AUTOSAR XML (schema 4-0-3)
standard types defined: Boolean, UInt16, UInt32
package /AUTOSAR_Platform/DataConstrs
  range DC_Boolean: raw 0..1
  range DC_UInt16: raw 0..65535
package /PATAC/MSM/ComponentTypes
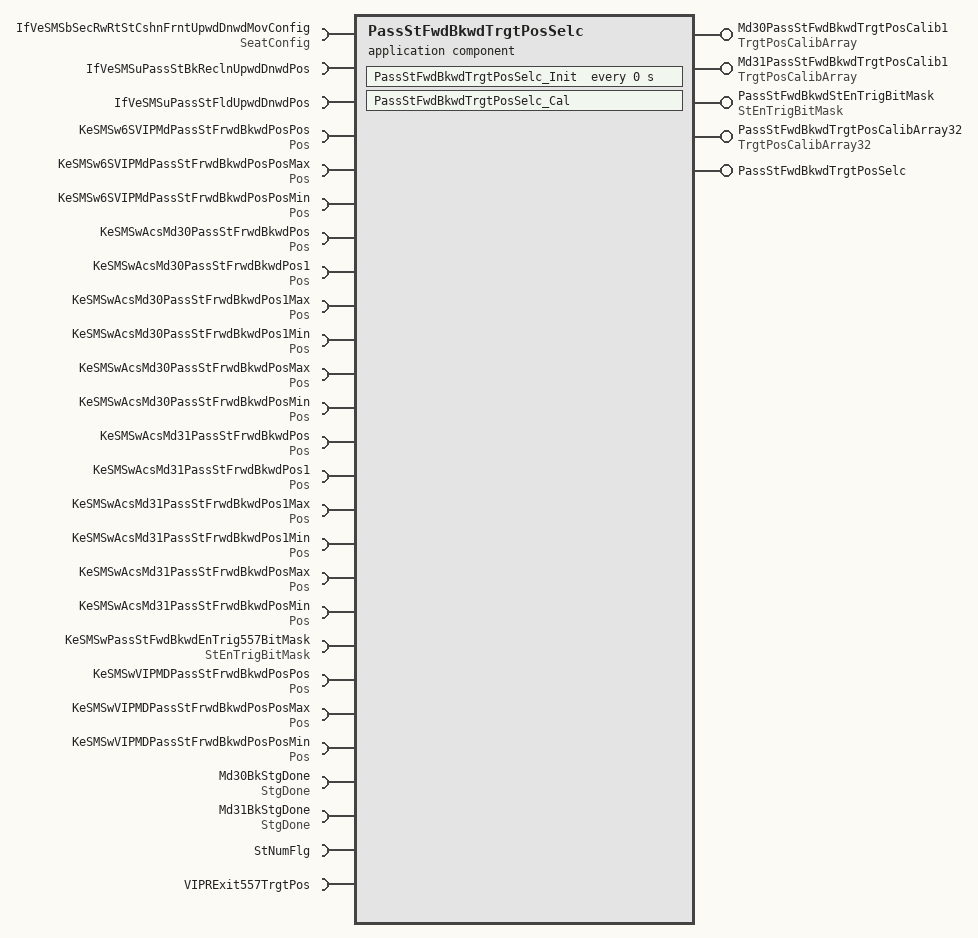
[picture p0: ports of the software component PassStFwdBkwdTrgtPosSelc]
  application sw component type PassStFwdBkwdTrgtPosSelc
    5 x provide port:
      Md30PassStFwdBkwdTrgtPosCalib1: nonqueued-sender-com-spec{data-element=TrgtPosArray, init-value=[4095, 4095, 4095]}, provided-interface=TrgtPosCalibArray
      Md31PassStFwdBkwdTrgtPosCalib1: nonqueued-sender-com-spec{data-element=TrgtPosArray, init-value=[4095, 4095, 4095]}, provided-interface=TrgtPosCalibArray
      PassStFwdBkwdStEnTrigBitMask: nonqueued-sender-com-spec{data-element=StEnTrigBitMask/Val, init-value=0}, provided-interface=StEnTrigBitMask
      PassStFwdBkwdTrgtPosCalibArray32: nonqueued-sender-com-spec{data-element=TrgtPosArray32, init-value=96 x 4095}, provided-interface=TrgtPosCalibArray32
      PassStFwdBkwdTrgtPosSelc: server-com-spec{operation=Cal, queue-length=1}, provided-interface=PassStFwdBkwdTrgtPosSelc
    26 x require port:
      IfVeSMSbSecRwRtStCshnFrntUpwdDnwdMovConfig: nonqueued-receiver-com-spec{data-element=SeatConfig/Val, filter=data-filter-type=ALWAYS, init-value=0}, required-interface=SeatConfig
      IfVeSMSuPassStBkReclnUpwdDnwdPos: nonqueued-receiver-com-spec{data-element=IfVeSMSuPassStBkReclnUpwdDnwdPos/Val, filter=data-filter-type=ALWAYS, init-value=0}, required-interface=IfVeSMSuPassStBkReclnUpwdDnwdPos
      IfVeSMSuPassStFldUpwdDnwdPos: nonqueued-receiver-com-spec{data-element=IfVeSMSuPassStFldUpwdDnwdPos/Val, filter=data-filter-type=ALWAYS, init-value=0}, required-interface=IfVeSMSuPassStFldUpwdDnwdPos
      KeSMSw6SVIPMdPassStFrwdBkwdPosPos: parameter-require-com-spec{init-value=0, parameter=Pos/Val}, required-interface=Pos
      KeSMSw6SVIPMdPassStFrwdBkwdPosPosMax: parameter-require-com-spec{init-value=0, parameter=Pos/Val}, required-interface=Pos
      KeSMSw6SVIPMdPassStFrwdBkwdPosPosMin: parameter-require-com-spec{init-value=0, parameter=Pos/Val}, required-interface=Pos
      KeSMSwAcsMd30PassStFrwdBkwdPos: parameter-require-com-spec{init-value=0, parameter=Pos/Val}, required-interface=Pos
      KeSMSwAcsMd30PassStFrwdBkwdPos1: parameter-require-com-spec{init-value=0, parameter=Pos/Val}, required-interface=Pos
      KeSMSwAcsMd30PassStFrwdBkwdPos1Max: parameter-require-com-spec{init-value=0, parameter=Pos/Val}, required-interface=Pos
      KeSMSwAcsMd30PassStFrwdBkwdPos1Min: parameter-require-com-spec{init-value=0, parameter=Pos/Val}, required-interface=Pos
      KeSMSwAcsMd30PassStFrwdBkwdPosMax: parameter-require-com-spec{init-value=0, parameter=Pos/Val}, required-interface=Pos
      KeSMSwAcsMd30PassStFrwdBkwdPosMin: parameter-require-com-spec{init-value=0, parameter=Pos/Val}, required-interface=Pos
      KeSMSwAcsMd31PassStFrwdBkwdPos: parameter-require-com-spec{init-value=0, parameter=Pos/Val}, required-interface=Pos
      KeSMSwAcsMd31PassStFrwdBkwdPos1: parameter-require-com-spec{init-value=0, parameter=Pos/Val}, required-interface=Pos
      KeSMSwAcsMd31PassStFrwdBkwdPos1Max: parameter-require-com-spec{init-value=0, parameter=Pos/Val}, required-interface=Pos
      KeSMSwAcsMd31PassStFrwdBkwdPos1Min: parameter-require-com-spec{init-value=0, parameter=Pos/Val}, required-interface=Pos
      KeSMSwAcsMd31PassStFrwdBkwdPosMax: parameter-require-com-spec{init-value=0, parameter=Pos/Val}, required-interface=Pos
      KeSMSwAcsMd31PassStFrwdBkwdPosMin: parameter-require-com-spec{init-value=0, parameter=Pos/Val}, required-interface=Pos
      KeSMSwPassStFwdBkwdEnTrig557BitMask: parameter-require-com-spec{init-value=6153, parameter=StEnTrigBitMask/Val}, required-interface=StEnTrigBitMask
      KeSMSwVIPMDPassStFrwdBkwdPosPos: parameter-require-com-spec{init-value=0, parameter=Pos/Val}, required-interface=Pos
      KeSMSwVIPMDPassStFrwdBkwdPosPosMax: parameter-require-com-spec{init-value=0, parameter=Pos/Val}, required-interface=Pos
      KeSMSwVIPMDPassStFrwdBkwdPosPosMin: parameter-require-com-spec{init-value=0, parameter=Pos/Val}, required-interface=Pos
      Md30BkStgDone: nonqueued-receiver-com-spec{data-element=StgDone/Val, filter=data-filter-type=ALWAYS, init-value=0}, required-interface=StgDone
      Md31BkStgDone: nonqueued-receiver-com-spec{data-element=StgDone/Val, filter=data-filter-type=ALWAYS, init-value=0}, required-interface=StgDone
      StNumFlg: required-interface=StNumFlg
        required-com-specs:
          data-element=Is4s, filter=data-filter-type=ALWAYS, init-value=0
          data-element=Is6s, filter=data-filter-type=ALWAYS, init-value=0
          data-element=Is6s7s, filter=data-filter-type=ALWAYS, init-value=0
          data-element=Is7s, filter=data-filter-type=ALWAYS, init-value=0
      VIPRExit557TrgtPos: required-com-specs=[Get, Set], required-interface=VIPRExit557TrgtPos
    behavior PassStFwdBkwdTrgtPosSelc_InternalBehavior
      operation invoked event OIT_PassStFwdBkwdTrgtPosSelc_Cal_PassStFwdBkwdTrgtPosSelc_Cal: start-on-event=PassStFwdBkwdTrgtPosSelc_Cal, operation=PassStFwdBkwdTrgtPosSelc.Cal
      timing event PassStFwdBkwdTrgtPosSelc_InitEvent: start-on-event=PassStFwdBkwdTrgtPosSelc_Init, period=0
      runnable PassStFwdBkwdTrgtPosSelc_Cal
        data-receive-point-by-arguments:
          9 x access:
            REC_IfVeSMSbSecRwRtStCshnFrntUpwdDnwdMovConfig_Val: accessed-variable=IfVeSMSbSecRwRtStCshnFrntUpwdDnwdMovConfig.Val
            REC_IfVeSMSuPassStBkReclnUpwdDnwdPos_Val: accessed-variable=IfVeSMSuPassStBkReclnUpwdDnwdPos.Val
            REC_IfVeSMSuPassStFldUpwdDnwdPos_Val: accessed-variable=IfVeSMSuPassStFldUpwdDnwdPos.Val
            REC_Md30BkStgDone_Val: accessed-variable=Md30BkStgDone.Val
            REC_Md31BkStgDone_Val: accessed-variable=Md31BkStgDone.Val
            REC_StNumFlg_Is4s: accessed-variable=StNumFlg.Is4s
            REC_StNumFlg_Is6s: accessed-variable=StNumFlg.Is6s
            REC_StNumFlg_Is6s7s: accessed-variable=StNumFlg.Is6s7s
            REC_StNumFlg_Is7s: accessed-variable=StNumFlg.Is7s
        data-send-points:
          4 x access:
            SEND_Md30PassStFwdBkwdTrgtPosCalib1_TrgtPosArray: accessed-variable=Md30PassStFwdBkwdTrgtPosCalib1.TrgtPosArray
            SEND_Md31PassStFwdBkwdTrgtPosCalib1_TrgtPosArray: accessed-variable=Md31PassStFwdBkwdTrgtPosCalib1.TrgtPosArray
            SEND_PassStFwdBkwdStEnTrigBitMask_Val: accessed-variable=PassStFwdBkwdStEnTrigBitMask.Val
            SEND_PassStFwdBkwdTrgtPosCalibArray32_TrgtPosArray32: accessed-variable=PassStFwdBkwdTrgtPosCalibArray32.TrgtPosArray32
        19 x parameter access:
          PA_KeSMSw6SVIPMdPassStFrwdBkwdPosPos_Val: accessed-parameter=KeSMSw6SVIPMdPassStFrwdBkwdPosPos.Val
          PA_KeSMSw6SVIPMdPassStFrwdBkwdPosPosMax_Val: accessed-parameter=KeSMSw6SVIPMdPassStFrwdBkwdPosPosMax.Val
          PA_KeSMSw6SVIPMdPassStFrwdBkwdPosPosMin_Val: accessed-parameter=KeSMSw6SVIPMdPassStFrwdBkwdPosPosMin.Val
          PA_KeSMSwAcsMd30PassStFrwdBkwdPos_Val: accessed-parameter=KeSMSwAcsMd30PassStFrwdBkwdPos.Val
          PA_KeSMSwAcsMd30PassStFrwdBkwdPos1_Val: accessed-parameter=KeSMSwAcsMd30PassStFrwdBkwdPos1.Val
          PA_KeSMSwAcsMd30PassStFrwdBkwdPos1Max_Val: accessed-parameter=KeSMSwAcsMd30PassStFrwdBkwdPos1Max.Val
          PA_KeSMSwAcsMd30PassStFrwdBkwdPos1Min_Val: accessed-parameter=KeSMSwAcsMd30PassStFrwdBkwdPos1Min.Val
          PA_KeSMSwAcsMd30PassStFrwdBkwdPosMax_Val: accessed-parameter=KeSMSwAcsMd30PassStFrwdBkwdPosMax.Val
          PA_KeSMSwAcsMd30PassStFrwdBkwdPosMin_Val: accessed-parameter=KeSMSwAcsMd30PassStFrwdBkwdPosMin.Val
          PA_KeSMSwAcsMd31PassStFrwdBkwdPos_Val: accessed-parameter=KeSMSwAcsMd31PassStFrwdBkwdPos.Val
          PA_KeSMSwAcsMd31PassStFrwdBkwdPos1_Val: accessed-parameter=KeSMSwAcsMd31PassStFrwdBkwdPos1.Val
          PA_KeSMSwAcsMd31PassStFrwdBkwdPos1Max_Val: accessed-parameter=KeSMSwAcsMd31PassStFrwdBkwdPos1Max.Val
          PA_KeSMSwAcsMd31PassStFrwdBkwdPos1Min_Val: accessed-parameter=KeSMSwAcsMd31PassStFrwdBkwdPos1Min.Val
          PA_KeSMSwAcsMd31PassStFrwdBkwdPosMax_Val: accessed-parameter=KeSMSwAcsMd31PassStFrwdBkwdPosMax.Val
          PA_KeSMSwAcsMd31PassStFrwdBkwdPosMin_Val: accessed-parameter=KeSMSwAcsMd31PassStFrwdBkwdPosMin.Val
          PA_KeSMSwPassStFwdBkwdEnTrig557BitMask_Val: accessed-parameter=KeSMSwPassStFwdBkwdEnTrig557BitMask.Val
          PA_KeSMSwVIPMDPassStFrwdBkwdPosPos_Val: accessed-parameter=KeSMSwVIPMDPassStFrwdBkwdPosPos.Val
          PA_KeSMSwVIPMDPassStFrwdBkwdPosPosMax_Val: accessed-parameter=KeSMSwVIPMDPassStFrwdBkwdPosPosMax.Val
          PA_KeSMSwVIPMDPassStFrwdBkwdPosPosMin_Val: accessed-parameter=KeSMSwVIPMDPassStFrwdBkwdPosPosMin.Val
        sync call SC_VIPRExit557TrgtPos_Get: operation=VIPRExit557TrgtPos.Get, timeout=0
      runnable PassStFwdBkwdTrgtPosSelc_Init
        19 x parameter access:
          PA_KeSMSw6SVIPMdPassStFrwdBkwdPosPos_Val: accessed-parameter=KeSMSw6SVIPMdPassStFrwdBkwdPosPos.Val
          PA_KeSMSw6SVIPMdPassStFrwdBkwdPosPosMax_Val: accessed-parameter=KeSMSw6SVIPMdPassStFrwdBkwdPosPosMax.Val
          PA_KeSMSw6SVIPMdPassStFrwdBkwdPosPosMin_Val: accessed-parameter=KeSMSw6SVIPMdPassStFrwdBkwdPosPosMin.Val
          PA_KeSMSwAcsMd30PassStFrwdBkwdPos_Val: accessed-parameter=KeSMSwAcsMd30PassStFrwdBkwdPos.Val
          PA_KeSMSwAcsMd30PassStFrwdBkwdPos1_Val: accessed-parameter=KeSMSwAcsMd30PassStFrwdBkwdPos1.Val
          PA_KeSMSwAcsMd30PassStFrwdBkwdPos1Max_Val: accessed-parameter=KeSMSwAcsMd30PassStFrwdBkwdPos1Max.Val
          PA_KeSMSwAcsMd30PassStFrwdBkwdPos1Min_Val: accessed-parameter=KeSMSwAcsMd30PassStFrwdBkwdPos1Min.Val
          PA_KeSMSwAcsMd30PassStFrwdBkwdPosMax_Val: accessed-parameter=KeSMSwAcsMd30PassStFrwdBkwdPosMax.Val
          PA_KeSMSwAcsMd30PassStFrwdBkwdPosMin_Val: accessed-parameter=KeSMSwAcsMd30PassStFrwdBkwdPosMin.Val
          PA_KeSMSwAcsMd31PassStFrwdBkwdPos_Val: accessed-parameter=KeSMSwAcsMd31PassStFrwdBkwdPos.Val
          PA_KeSMSwAcsMd31PassStFrwdBkwdPos1_Val: accessed-parameter=KeSMSwAcsMd31PassStFrwdBkwdPos1.Val
          PA_KeSMSwAcsMd31PassStFrwdBkwdPos1Max_Val: accessed-parameter=KeSMSwAcsMd31PassStFrwdBkwdPos1Max.Val
          PA_KeSMSwAcsMd31PassStFrwdBkwdPos1Min_Val: accessed-parameter=KeSMSwAcsMd31PassStFrwdBkwdPos1Min.Val
          PA_KeSMSwAcsMd31PassStFrwdBkwdPosMax_Val: accessed-parameter=KeSMSwAcsMd31PassStFrwdBkwdPosMax.Val
          PA_KeSMSwAcsMd31PassStFrwdBkwdPosMin_Val: accessed-parameter=KeSMSwAcsMd31PassStFrwdBkwdPosMin.Val
          PA_KeSMSwPassStFwdBkwdEnTrig557BitMask_Val: accessed-parameter=KeSMSwPassStFwdBkwdEnTrig557BitMask.Val
          PA_KeSMSwVIPMDPassStFrwdBkwdPosPos_Val: accessed-parameter=KeSMSwVIPMDPassStFrwdBkwdPosPos.Val
          PA_KeSMSwVIPMDPassStFrwdBkwdPosPosMax_Val: accessed-parameter=KeSMSwVIPMDPassStFrwdBkwdPosPosMax.Val
          PA_KeSMSwVIPMDPassStFrwdBkwdPosPosMin_Val: accessed-parameter=KeSMSwVIPMDPassStFrwdBkwdPosPosMin.Val
  swc implementation PassStFwdBkwdTrgtPosSelc_Implementation: behavior=PassStFwdBkwdTrgtPosSelc_InternalBehavior
    code-descriptors:
      code Default: artifact-descriptors=autosar-engineering-object={short-label=Default, category=SWSRC}
package /PATAC/MSM/ModeAdjust/CalPortInterface
  parameter interface Pos
    parameter data prototype Val: sw-calibration-access=READ-WRITE, type=UInt16
  parameter interface StEnTrigBitMask
    parameter data prototype Val: sw-calibration-access=READ-WRITE, type=UInt32
package /PATAC/MSM/ModeAdjust/DataType
  impl type TrgtPosCalibArray: category=ARRAY, sw-calibration-access=READ-ONLY, type-emitter=RTE  # 0:pos 1:max 2:min
    element Element: array-size=3, array-size-semantics=FIXED-SIZE, implementation-data-type=UInt16, invalid-value=0
  impl type TrgtPosCalibArray32: category=ARRAY, sw-calibration-access=READ-ONLY, type-emitter=RTE  # 0:pos 1:max 2:min
    element Element: array-size=96, array-size-semantics=FIXED-SIZE, implementation-data-type=UInt16, invalid-value=0
package /PATAC/MSM/ModeAdjust/PortInterface
  client server interface PassStFwdBkwdTrgtPosSelc
    operation Cal
  client server interface VIPRExit557TrgtPos
    operation Get
      11 x arg, all with type=UInt16, direction=OUT, server-argument-impl-policy=USE-ARGUMENT-TYPE:
        SecRwRtStBkReclnTrgtPos
        SecRwRtStZeroTrgtPos
        SecRwRtStLgrstUpwdDnwdTrgtPos
        SecRwRtStLgrstInwdOtwdTrgtPos
        ThdRwLtStBkReclnTrgtPos
        ThdRwLtStFwdBkwdTrgtPos
        ThdRwRtStBkReclnTrgtPos
        ThdRwRtStFwdBkwdTrgtPos
        PassStBkReclnTrgtPos
        PassStFwdBkwdTrgtPos
        SecRwRtStFwdBkwdTrgtPos
    operation Set
  6 x sender receiver interface:
    IfVeSMSuPassStFldUpwdDnwdPos: invalidation-policy{data-element=IfVeSMSuPassStFldUpwdDnwdPos/Val, handle-invalid=DONT-INVALIDATE}
      data Val: type=UInt16
    StEnTrigBitMask: invalidation-policy{data-element=StEnTrigBitMask/Val, handle-invalid=DONT-INVALIDATE}
      data Val: type=UInt32
    StgDone: invalidation-policy{data-element=StgDone/Val, handle-invalid=DONT-INVALIDATE}
      data Val: type=Boolean
    StNumFlg
      4 x data, all with type=Boolean:
        Is4s
        Is6s
        Is6s7s
        Is7s
      invalidation-policys:
        data-element=Is4s, handle-invalid=DONT-INVALIDATE
        data-element=Is6s, handle-invalid=DONT-INVALIDATE
        data-element=Is6s7s, handle-invalid=DONT-INVALIDATE
        data-element=Is7s, handle-invalid=DONT-INVALIDATE
    TrgtPosCalibArray: invalidation-policy{data-element=TrgtPosArray, handle-invalid=DONT-INVALIDATE}
      data TrgtPosArray: type=TrgtPosCalibArray  # 0:Pos 1:Max 2:Min
    TrgtPosCalibArray32: invalidation-policy{data-element=TrgtPosArray32, handle-invalid=DONT-INVALIDATE}
      data TrgtPosArray32: type=TrgtPosCalibArray32  # 0:Pos 1:Max 2:Min
package /PATAC/MSM/PortInterfaces
  sender receiver interface IfVeSMSuPassStBkReclnUpwdDnwdPos: invalidation-policy{data-element=IfVeSMSuPassStBkReclnUpwdDnwdPos/Val, handle-invalid=DONT-INVALIDATE}
    data Val: type=UInt16
  sender receiver interface SeatConfig: invalidation-policy{data-element=SeatConfig/Val, handle-invalid=DONT-INVALIDATE}
    data Val: type=Boolean
